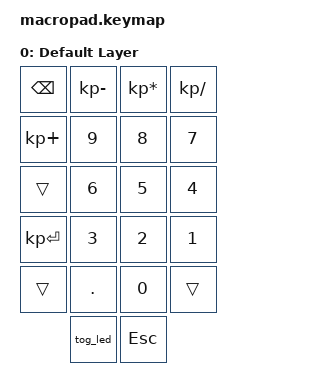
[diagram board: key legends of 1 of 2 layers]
// This file was generated from a template. Edit it to match your keyboard.
// See https://zmk.dev/docs/development/hardware-integration/new-shield for more instructions.

#include <behaviors.dtsi>
#include <dt-bindings/zmk/keys.h>
#include <dt-bindings/zmk/bt.h>
#include <dt-bindings/zmk/backlight.h>

/ {
    // toggles led when switching to lower_layer
    macros {
        tog_led: tog_led {
            compatible = "zmk,behavior-macro";
            #binding-cells = <0>;
            wait-ms = <0>;
            tap-ms = <0>;
            bindings
                = <&tog 1>
                , <&bl BL_TOG>
                ;
        };
    };

    // Define a default keymap here.
    // See https://zmk.dev/docs/development/hardware-integration/new-shield#default-keymap.
    keymap {
        compatible = "zmk,keymap";

        default_layer { // layer 0
            display-name = "Default Layer";
            // | | |fn1|fn2|
            // |fn3 |/ |* |- |
            // |7 |8 |9 |+ |
            // |4 |5 |6 |+ |
            // |1 |2 |3 |etr |
            // |0 |0 |. |etr |

            // | | |22 |21 |
            // |4 |3 |2 |1 |
            // |8 |7 |6 |5* |
            // |12 |11 |10 |9 |
            // |16 |15 |14 |13* |
            // |20 |19* |18 |17 |
            bindings = <
                &kp BSPC &kp KP_MINUS &kp KP_MULTIPLY &kp KP_DIVIDE              
                &kp KP_PLUS &kp N9 &kp N8 &kp N7
                &trans &kp N6 &kp N5 &kp N4 
                &kp KP_ENTER &kp N3 &kp N2 &kp N1 
                &trans &kp DOT &kp N0 &trans
                &tog_led &kp ESC // 21 and 22
            >;
        };
        lower_layer { // layer 1
            display-name = "Lower Layer";
            bindings = <
                &trans &trans &trans &bootloader
                // &bt BT_SEL 0  &bt BT_SEL 1 &bt BT_SEL 2 &bt BT_CLR
                &bt BT_SEL 0  &trans &trans &bt BT_CLR
                &trans &trans &trans &trans
                &trans &trans &trans &trans
                &trans &trans &trans 
                &trans &trans
            >;
        };
        
        extra_layer_2 {
            status = "reserved";
        };
    };
};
